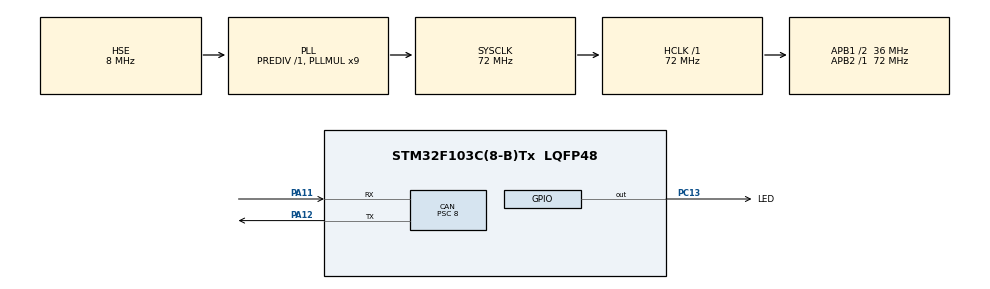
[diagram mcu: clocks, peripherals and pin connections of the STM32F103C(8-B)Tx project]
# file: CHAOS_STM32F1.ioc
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CAN.AWUM=ENABLE
CAN.BS1=CAN_BS1_3TQ
CAN.BS2=CAN_BS2_5TQ
CAN.CalculateBaudRate=500000
CAN.CalculateTimeBit=2000
CAN.CalculateTimeQuantum=222.22222222222223
CAN.NART=ENABLE
CAN.Prescaler=8
Mcu.Family=STM32F1
Mcu.Name=STM32F103C(8-B)Tx
Mcu.Package=LQFP48
NVIC.PriorityGroup=NVIC_PRIORITYGROUP_4
NVIC.TIM2_IRQn=true\:0\:0\:false\:false\:true\:true\:true\:true
PA11.Mode=CAN_Activate
PA11.Signal=CAN_RX
PA12.Mode=CAN_Activate
PA12.Signal=CAN_TX
PA13.Mode=Serial_Wire
PA13.Signal=SYS_JTMS-SWDIO
PA14.Mode=Serial_Wire
PA14.Signal=SYS_JTCK-SWCLK
PC13-TAMPER-RTC.GPIO_Label=LED
PC13-TAMPER-RTC.PinState=GPIO_PIN_SET
PC13-TAMPER-RTC.Signal=GPIO_Output
PD0-OSC_IN.Mode=HSE-External-Oscillator
PD0-OSC_IN.Signal=RCC_OSC_IN
PD1-OSC_OUT.Mode=HSE-External-Oscillator
PD1-OSC_OUT.Signal=RCC_OSC_OUT
ProjectManager.HeapSize=0x200
ProjectManager.StackSize=0x400
ProjectManager.TargetToolchain=STM32CubeIDE
RCC.AHBFreq_Value=72000000
RCC.APB1CLKDivider=RCC_HCLK_DIV2
RCC.APB1Freq_Value=36000000
RCC.APB1TimFreq_Value=72000000
RCC.APB2Freq_Value=72000000
RCC.APB2TimFreq_Value=72000000
RCC.HCLKFreq_Value=72000000
RCC.PLLMUL=RCC_PLL_MUL9
RCC.PLLSourceVirtual=RCC_PLLSOURCE_HSE
RCC.SYSCLKFreq_VALUE=72000000
RCC.SYSCLKSource=RCC_SYSCLKSOURCE_PLLCLK
RCC.USBFreq_Value=48000000
RCC.USBPrescaler=RCC_USBCLKSOURCE_PLL_DIV1_5
TIM2.Period=10
TIM2.Prescaler=7200
VP_TIM2_VS_ClockSourceINT.Mode=Internal
board=custom

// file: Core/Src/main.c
/* USER CODE BEGIN Header */
/**
  ******************************************************************************
  * @file           : main.c
  * @brief          : Main program body
  ******************************************************************************
  * @attention
  *
  * Copyright (c) 2024 STMicroelectronics.
  * All rights reserved.
  *
  * This software is licensed under terms that can be found in the LICENSE file
  * in the root directory of this software component.
  * If no LICENSE file comes with this software, it is provided AS-IS.
  *
  ******************************************************************************
  */
/* USER CODE END Header */
#include "main.h"

/* USER CODE BEGIN Includes */
#include "os.h"
#include "strings.h"
/* USER CODE END Includes */

CAN_HandleTypeDef hcan;

TIM_HandleTypeDef htim2;

/* USER CODE BEGIN PV */

CAN_TxHeaderTypeDef TxHeader;
uint8_t TxData[8];
uint32_t TxMailbox;

/* USER CODE END PV */

void SystemClock_Config(void);
static void MX_GPIO_Init(void);
static void MX_TIM2_Init(void);
static void MX_CAN_Init(void);

/* USER CODE BEGIN 0 */

void HAL_TIM_PeriodElapsedCallback(TIM_HandleTypeDef *htim)
{
  if(htim->Instance == TIM2)
  {
    /* OS tick service */
    Os_Tick();
  }
}

void CAN_SendMessage(void)
{
    // Configura header del messaggio
    TxHeader.DLC = 8;                    // Numero di byte (da 0 a 8)
    TxHeader.ExtId = 0x01;               // ID esteso (se usi esteso)
    TxHeader.IDE = CAN_ID_STD;           // Usa CAN_ID_EXT se vuoi esteso
    TxHeader.RTR = CAN_RTR_DATA;         // Tipo messaggio: DATA FRAME
    TxHeader.StdId = 0x321;              // ID standard (11 bit)
    TxHeader.TransmitGlobalTime = DISABLE;

    // Dati da inviare
    TxData[0] = 0xAB;
    TxData[1] = 0xCD;
    TxData[2] = 0x12;
    TxData[3] = 0x34;

    // Invia il messaggio
    if (HAL_CAN_AddTxMessage(&hcan, &TxHeader, TxData, &TxMailbox) != HAL_OK)
    {
        // Errore trasmissione
        Error_Handler();
    }
}

/* MyTask_1 function */
TASK(MyTask_1)
{
  char *data = "LED_1 Toggle \r\n";

  /* Toggle LED */
  //CDC_Transmit_FS((uint8_t*)data, strlen(data));
  HAL_GPIO_TogglePin(LED_GPIO_Port, LED_Pin);
  HAL_Delay(10);
  HAL_GPIO_TogglePin(LED_GPIO_Port, LED_Pin);
  HAL_Delay(100);

  /* Task Termination */
  Os_TerminateTask();
}

/* MyTask_2 function */
TASK(MyTask_2)
{
  char *data = "LED_2 Toggle \r\n";

  /* Toggle LED */
 // CDC_Transmit_FS((uint8_t*)data, strlen(data));
  HAL_GPIO_TogglePin(LED_GPIO_Port, LED_Pin);
  HAL_Delay(10);
  HAL_GPIO_TogglePin(LED_GPIO_Port, LED_Pin);
  HAL_Delay(100);

  /* Send can messages */
  CAN_SendMessage();

  /* Task Termination */
  Os_TerminateTask();
}

/* USER CODE END 0 */

int main(void)
{

  /* MCU Configuration--------------------------------------------------------*/

  /* Reset of all peripherals, Initializes the Flash interface and the Systick. */
  HAL_Init();

  /* Configure the system clock */
  SystemClock_Config();

  /* Initialize all configured peripherals */
  MX_GPIO_Init();
  MX_TIM2_Init();
  MX_CAN_Init();
  /* USER CODE BEGIN 2 */

  HAL_TIM_Base_Start_IT(&htim2);

  HAL_CAN_Start(&hcan);

  /* Start OS */
  Os_Start();

  /* USER CODE END 2 */

  /* Infinite loop */
  while (1)
  {

  }
}

void SystemClock_Config(void)
{
  RCC_OscInitTypeDef RCC_OscInitStruct = {0};
  RCC_ClkInitTypeDef RCC_ClkInitStruct = {0};

  /** Initializes the RCC Oscillators according to the specified parameters
  * in the RCC_OscInitTypeDef structure.
  */
  RCC_OscInitStruct.OscillatorType = RCC_OSCILLATORTYPE_HSE;
  RCC_OscInitStruct.HSEState = RCC_HSE_ON;
  RCC_OscInitStruct.HSEPredivValue = RCC_HSE_PREDIV_DIV1;
  RCC_OscInitStruct.HSIState = RCC_HSI_ON;
  RCC_OscInitStruct.PLL.PLLState = RCC_PLL_ON;
  RCC_OscInitStruct.PLL.PLLSource = RCC_PLLSOURCE_HSE;
  RCC_OscInitStruct.PLL.PLLMUL = RCC_PLL_MUL9;
  if (HAL_RCC_OscConfig(&RCC_OscInitStruct) != HAL_OK)
  {
    Error_Handler();
  }

  /** Initializes the CPU, AHB and APB buses clocks
  */
  RCC_ClkInitStruct.ClockType = RCC_CLOCKTYPE_HCLK|RCC_CLOCKTYPE_SYSCLK
                              |RCC_CLOCKTYPE_PCLK1|RCC_CLOCKTYPE_PCLK2;
  RCC_ClkInitStruct.SYSCLKSource = RCC_SYSCLKSOURCE_PLLCLK;
  RCC_ClkInitStruct.AHBCLKDivider = RCC_SYSCLK_DIV1;
  RCC_ClkInitStruct.APB1CLKDivider = RCC_HCLK_DIV2;
  RCC_ClkInitStruct.APB2CLKDivider = RCC_HCLK_DIV1;

  if (HAL_RCC_ClockConfig(&RCC_ClkInitStruct, FLASH_LATENCY_2) != HAL_OK)
  {
    Error_Handler();
  }
}

static void MX_CAN_Init(void)
{

  hcan.Instance = CAN1;
  hcan.Init.Prescaler = 8;
  hcan.Init.Mode = CAN_MODE_NORMAL;
  hcan.Init.SyncJumpWidth = CAN_SJW_1TQ;
  hcan.Init.TimeSeg1 = CAN_BS1_3TQ;
  hcan.Init.TimeSeg2 = CAN_BS2_5TQ;
  hcan.Init.TimeTriggeredMode = DISABLE;
  hcan.Init.AutoBusOff = DISABLE;
  hcan.Init.AutoWakeUp = ENABLE;
  hcan.Init.AutoRetransmission = ENABLE;
  hcan.Init.ReceiveFifoLocked = DISABLE;
  hcan.Init.TransmitFifoPriority = DISABLE;
  if (HAL_CAN_Init(&hcan) != HAL_OK)
  {
    Error_Handler();
  }

}

static void MX_TIM2_Init(void)
{

  TIM_ClockConfigTypeDef sClockSourceConfig = {0};
  TIM_MasterConfigTypeDef sMasterConfig = {0};

  htim2.Instance = TIM2;
  htim2.Init.Prescaler = 7200;
  htim2.Init.CounterMode = TIM_COUNTERMODE_UP;
  htim2.Init.Period = 10;
  htim2.Init.ClockDivision = TIM_CLOCKDIVISION_DIV1;
  htim2.Init.AutoReloadPreload = TIM_AUTORELOAD_PRELOAD_DISABLE;
  if (HAL_TIM_Base_Init(&htim2) != HAL_OK)
  {
    Error_Handler();
  }
  sClockSourceConfig.ClockSource = TIM_CLOCKSOURCE_INTERNAL;
  if (HAL_TIM_ConfigClockSource(&htim2, &sClockSourceConfig) != HAL_OK)
  {
    Error_Handler();
  }
  sMasterConfig.MasterOutputTrigger = TIM_TRGO_RESET;
  sMasterConfig.MasterSlaveMode = TIM_MASTERSLAVEMODE_DISABLE;
  if (HAL_TIMEx_MasterConfigSynchronization(&htim2, &sMasterConfig) != HAL_OK)
  {
    Error_Handler();
  }

}

static void MX_GPIO_Init(void)
{
  GPIO_InitTypeDef GPIO_InitStruct = {0};

  /* GPIO Ports Clock Enable */
  __HAL_RCC_GPIOC_CLK_ENABLE();
  __HAL_RCC_GPIOD_CLK_ENABLE();
  __HAL_RCC_GPIOA_CLK_ENABLE();

  /*Configure GPIO pin Output Level */
  HAL_GPIO_WritePin(LED_GPIO_Port, LED_Pin, GPIO_PIN_SET);

  /*Configure GPIO pin : LED_Pin */
  GPIO_InitStruct.Pin = LED_Pin;
  GPIO_InitStruct.Mode = GPIO_MODE_OUTPUT_PP;
  GPIO_InitStruct.Pull = GPIO_NOPULL;
  GPIO_InitStruct.Speed = GPIO_SPEED_FREQ_LOW;
  HAL_GPIO_Init(LED_GPIO_Port, &GPIO_InitStruct);

}

void Error_Handler(void)
{
  __disable_irq();
  while (1)
  {
  }
}
